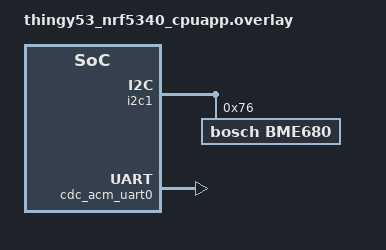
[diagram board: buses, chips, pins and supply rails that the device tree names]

&i2c1 {
    bme680@76 {
        compatible = "bosch,bme680";
        reg = <0x76>;
        label = "BME680";
    };
};

/ {
    chosen {
        zephyr,console = &cdc_acm_uart0;
    };
};

&zephyr_udc0 {
    cdc_acm_uart0: cdc_acm_uart0 {
        compatible = "zephyr,cdc-acm-uart";
        label = "CDC_ACM_0";
    };
};
